# apollo3c register map
Vendor: Ambiq Micro; Series: Apollo; File version: 1.0
CPU: CM4 r1p0, little endian, MPU, FPU, 3 interrupt priority bits
Registers are 32-bit, read-write, reset 0x0 unless marked. A register's access mark holds for its fields unless they carry their own. Offsets are from the block's base; [hi:lo] are bit positions; {n}, {i} and the like mark numbered series.

## SCARD — Serial ISO7816
Base 0x40080000
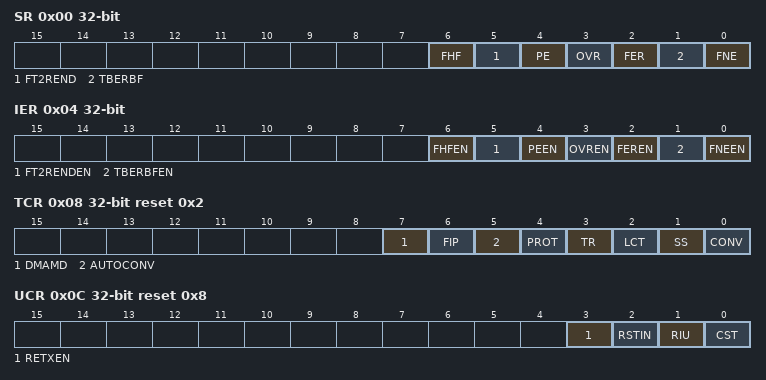
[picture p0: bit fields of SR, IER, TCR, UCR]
0x00 SR — ISO7816 interrupt status
  [6] FHF — FIFO Half Full.
    1=HALFFULL (FIFO is half full.)
  [5] FT2REND — TX to RX finished.
    1=CMPL (TX to RX completed.); 0=NOTCMPL (TX to RX not completed.)
  [4] PE — Parity Error.
    1=PEERR (Parity error.); 0=PENONE (No parity error.)
  [3] OVR — RX FIFO overflow.
    1=RXOVR (RX FIFO overflow.); 0=RXOVRNONE (RX FIFO no overflow.)
  [2] FER — Framing error.
    1=FRAMINGERR (Framing error.); 0=NOFRAMINGERR (No framing error detected.)
  [1] TBERBF — FIFO empty (transmit) or full (receive).
    1=TXFIFOEMPTY (Transmit: FIFO empty.); 0=TXFIFONOTEMPTY (Transmit: FIFO not empty.)
  [0] FNE — RX FIFO not empty.
    1=NOTEMPTY (RX FIFO not empty.); 0=EMPTY (RX FIFO empty.)
0x04 IER — ISO7816 interrupt enable
  [6] FHFEN — FIFO Half Full interrupt enable.
  [5] FT2RENDEN — TX to RX finished interrupt enable.
  [4] PEEN — Parity Error interrupt enable.
  [3] OVREN — RX FIFOI overflow interrupt enable.
  [2] FEREN — Framing error interrupt enable.
  [1] TBERBFEN — FIFO empty (transmit) or full (receive) interrupt enable.
  [0] FNEEN — RX FIFO not empty interrupt enable.
0x08 TCR reset 0x2 — ISO7816 transmit control
  [7] DMAMD — DMA direction.
  [6] FIP — Parity select.
  [5] AUTOCONV — Automatic conversion.
  [4] PROT — PROT control.
  [3] TR — Transmit/receive mode.
  [2] LCT — Fast TX to RX.
  [1] SS — Use first byte to configure conversion.
  [0] CONV — Conversion inversion control.
0x0C UCR reset 0x8 — ISO7816 user control
  [3] RETXEN — Enable TX/RX time configuration.
  [2] RSTIN — Reset polarity.
  [1] RIU — ISO7816 reset. This bit is write-only.
  [0] CST — Clock control.
0x10 DR — ISO7816 data
  [7:0] DR — Data register.
0x14 BPRL reset 0x74 — ISO7816 baud rate low
  [7:0] BPRL — Baud rate low
0x18 BPRH reset 0x1 — ISO7816 baud rate high
  [3:0] BPRH — Baud rate high
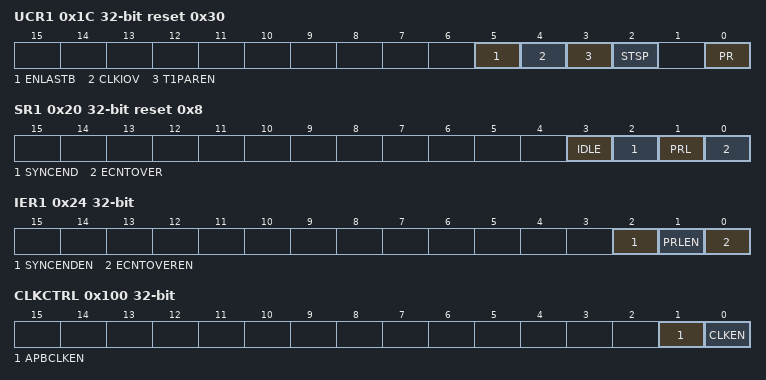
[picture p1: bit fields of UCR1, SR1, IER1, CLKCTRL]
0x1C UCR1 reset 0x30 — ISO7816 user control 1
  [5] ENLASTB — Enable last byte function.
  [4] CLKIOV — Output clock level.
  [3] T1PAREN — Parity check control.
  [2] STSP — ETU counter control. This bit is write-only.
  [0] PR — Query Card Detect.
0x20 SR1 reset 0x8 — ISO7816 interrupt status 1
  [3] IDLE — ISO7816 idle.
    1=IDLE (ISO7816 idle.); 0=ACTIVE (ISO7816 active.)
  [2] SYNCEND — Write complete synchronization.
    1=CMPL (Synchronization complete.); 0=INCMPL (Incomplete.)
  [1] PRL — Card insert/remove.
    1=INSREM (Card inserted/removed.)
  [0] ECNTOVER — ETU counter overflow.
    1=OVR (ETU overflow.)
0x24 IER1 — ISO7816 interrupt enable 1
  [2] SYNCENDEN — Write complete synchronization interrupt enable.
  [1] PRLEN — Card insert/remove interrupt enable.
  [0] ECNTOVEREN — ETU counter overflow interrupt enable.
0x28 ECNTL — ETU counter low
  [7:0] ECNTL — ETU counter low register.
0x2C ECNTH — ETU counter high
  [7:0] ECNTH — ETU counter high register.
0x30 GTR reset 0xFF — ISO7816 guard time configuration
  [7:0] GTR — Guard time configuration register.
0x34 RETXCNT reset 0x4 — ISO7816 resend count
  [3:0] RETXCNT — Resend count register.
0x38 RETXCNTRMI — ISO7816 resent count inquiry
  [3:0] RETXCNTRMI — Resent count inquiry register.
0x100 CLKCTRL — Clock Control
  [1] APBCLKEN — Enable the SCARD APB clock to run continuously.
  [0] CLKEN — Enable the serial source clock for SCARD.

## SECURITY — Security Interfaces
Base 0x40030000
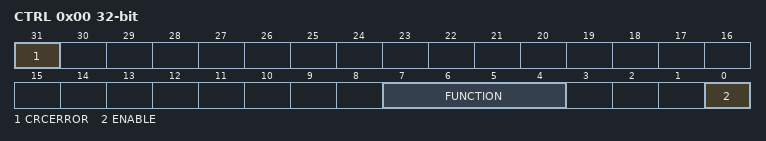
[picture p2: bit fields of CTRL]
0x00 CTRL — Control Register
  [31] CRCERROR — CRC Error Status - Set to 1 if an error occurs during a CRC operation. Cleared when CTRL register is written (with any value). Usually indicates an invalid address range.
  [7:4] FUNCTION — Function Select
    0=CRC32 (Perform CRC32 operation); 1=RAND (DMA pseudo-random number stream based on CRC value); 2=GENADDR (Generate DMA stream based on address)
  [0] ENABLE — Function Enable. Software should set the ENABLE bit to initiate a CRC operation. Hardware will clear the ENABLE bit upon completion.
0x10 SRCADDR — Source Addresss
  [31:0] ADDR — Source Buffer Address. Address may be byte aligned, but the length must be a multiple of 4 bits.
0x20 LEN — Length
  [23:2] LEN — Buffer size (bottom two bits assumed to be zero to ensure a multiple of 4 bytes)
0x30 RESULT — CRC Seed/Result Register
  [31:0] CRC — CRC Seed/Result. Software must seed the CRC with 0xFFFFFFFF before starting a CRC operation (unless the CRC is continued from a previous operation).
0x78 LOCKCTRL — LOCK Control Register
  [7:0] SELECT — LOCK Function Select register.
    1=CUSTOMER_KEY (Unlock Customer Key (access to top half of info0)); 0=NONE (Lock Control should be set to NONE when not in use.)
0x7C LOCKSTAT — LOCK Status Register
  [31:0] STATUS — LOCK Status register. This register is a bitmask for which resources are currently unlocked. These bits are one-hot per resource.
    1=CUSTOMER_KEY (Customer Key is unlocked (access is granted to top half of info0)); 0=NONE (No resources are unlocked)
{0x80+4i} KEY{i} (i=0..3)
  [31:0] KEY{i} — Bits [{32i+31}:{32i}] of the 128-bit key should be written to this register. To protect key values, the register always returns 0x00000000.
